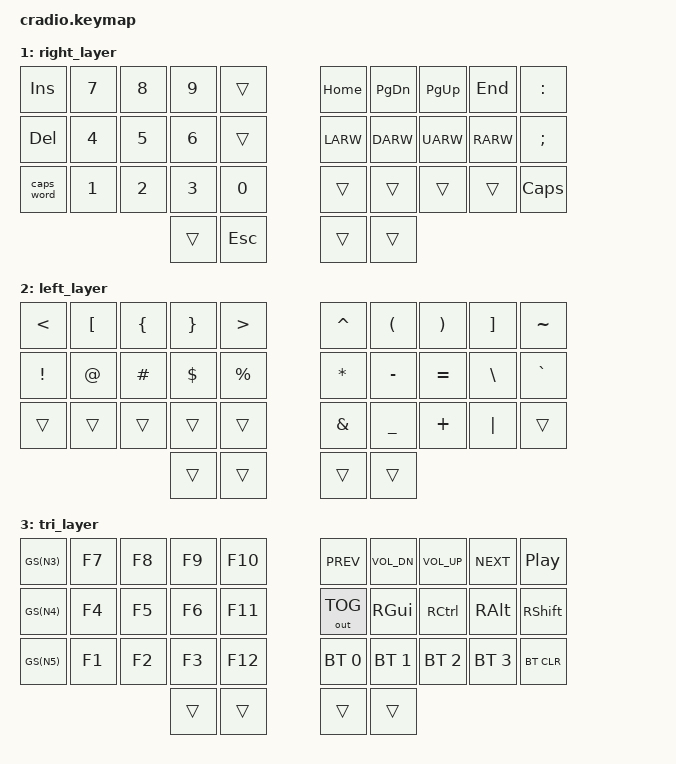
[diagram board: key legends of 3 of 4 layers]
// Copyright (c) 2022 The ZMK Contributors
// SPDX-License-Identifier: MIT

#include <behaviors.dtsi>
#include <dt-bindings/zmk/keys.h>
#include <dt-bindings/zmk/bt.h>
#include <dt-bindings/zmk/outputs.h>

/*           34 Keys
╭──────────────╮ ╭──────────────╮
│ 0  1  2  3  4│ │ 5  6  7  8  9│
│10 11 12 13 14│ │15 16 17 18 19│
│20 21 22 23 24│ │25 26 27 28 29│
╰────────╮30 31│ │32 33╭────────╯
         ╰─────╯ ╰─────╯         */

// Home row mods macro
#define HRML(k1,k2,k3,k4) &ht LSHFT k1  &ht LALT k2  &ht LCTRL k3  &ht LGUI k4
#define HRMR(k1,k2,k3,k4) &ht RGUI k1  &ht RCTRL k2  &ht RALT k3  &ht RSHFT k4

// GS - GUI+SHIFT, for screenshotting on mac
#define GS(k1) LS(LG(k1))

/ {
    combos {
        compatible = "zmk,combos";
        combo_lctrl {
            bindings = <&skq LCTRL>;
            key-positions = <1 2>;
            layers = <0 1 2>;
            require-prior-idle-ms = <100>;
        };
        combo_shift {
            bindings = <&skq LSHIFT>;
            key-positions = <7 8>;
            layers = <0 1 2>;
            require-prior-idle-ms = <100>;
        };
        combo_alt {
            bindings = <&skq LALT>;
            key-positions = <27 28>;
            layers = <0 1 2>;
            require-prior-idle-ms = <100>;
        };
        combo_cmd {
            bindings = <&skq LCMD>;
            key-positions = <21 22>;
            layers = <0 1 2>;
            require-prior-idle-ms = <100>;
        };
    };

    behaviors {
        skq: sticky_key_quick_release {
            compatible = "zmk,behavior-sticky-key";
            label = "STICKY_KEY_QUICK_RELEASE";
            #binding-cells = <1>;
            bindings = <&kp>;
            release-after-ms = <1000>;
            quick-release;
            ignore-modifiers;
        };
        ht: hold_tap {
            compatible = "zmk,behavior-hold-tap";
            #binding-cells = <2>;
            flavor = "tap-preferred";
            tapping-term-ms = <220>;
            quick-tap-ms = <150>;
            require-prior-idle-ms = <80>;
            bindings = <&kp>, <&kp>;
        };
    };

    conditional_layers {
        compatible = "zmk,conditional-layers";
        tri_layer {
            if-layers = <1 2>;
            then-layer = <3>;
        };
    };

    keymap {
        compatible = "zmk,keymap";
        default_layer {
            bindings = <
        //╭──────────┬──────────┬──────────┬──────────┬──────────╮   ╭──────────┬──────────┬──────────┬──────────┬──────────╮
        //│  Q       │  W       │  E       │  R       │  T       │   │  Y       │  U       │  I       │  O       │  P       │
            &kp Q      &kp W      &kp E      &kp R      &kp T          &kp Y      &kp U      &kp I      &kp O      &kp P
        //├──────────┼──────────┼──────────┼──────────┼──────────┤   ├──────────┼──────────┼──────────┼──────────┼──────────┤
        //│  A       │  S       │  D       │  F       │  G       │   │  H       │  J       │  K       │  L       │ ' "      │
            HRML(A,        S,         D,         F)     &kp G          &kp H      HRMR(J,        K,         L,        SQT)
        //├──────────┼──────────┼──────────┼──────────┼──────────┤   ├──────────┼──────────┼──────────┼──────────┼──────────┤
        //│  Z       │  X       │  C       │  V       │  B       │   │  N       │  M       │ , <      │ . >      │ / ?      │
            &kp Z      &kp X      &kp C      &kp V      &kp B          &kp N      &kp M      &kp COMMA  &kp DOT    &kp FSLH
        //╰──────────┴──────────┴──────────┼──────────┼──────────┤   ├──────────┼──────────┼──────────┴──────────┴──────────╯
                                            &lt 2 TAB   &kp ENTER     &kp SPACE  &lt 1 BSPC
        //                                 ╰──────────┴──────────╯   ╰──────────┴──────────╯
            >;
        };

        right_layer {
            bindings = <
        //╭──────────┬──────────┬──────────┬──────────┬──────────╮   ╭──────────┬──────────┬──────────┬──────────┬──────────╮
        //│ INSERT   │  7       │  8       │  9       │          │   │ HOME     │ PAGE DN  │ PAGE UP  │ END      │  :       │
            &kp INS    &kp N7     &kp N8     &kp N9     &trans         &kp HOME   &kp PG_DN  &kp PG_UP  &kp END    &kp COLON
        //├──────────┼──────────┼──────────┼──────────┼──────────┤   ├──────────┼──────────┼──────────┼──────────┼──────────┤
        //│ DELETE   │  4       │  5       │  6       │          │   │ LEFT     │ DOWN     │ UP       │ RIGHT    │  ;       │
            &kp DEL    &kp N4     &kp N5     &kp N6     &trans         &kp LARW   &kp DARW   &kp UARW   &kp RARW   &kp SEMI
        //├──────────┼──────────┼──────────┼──────────┼──────────┤   ├──────────┼──────────┼──────────┼──────────┼──────────┤
        //│ CAPS     │  1       │  2       │  3       │  0       │   │          │          │          │          │  CAPS L  │
           &caps_word  &kp N1     &kp N2     &kp N3     &kp N0         &trans     &trans     &trans     &trans     &kp CAPS
        //╰──────────┴──────────┴──────────┼──────────┼──────────┤   ├──────────┼──────────┼──────────┴──────────┴──────────╯
                                             &trans     &kp ESC        &trans     &trans
        //                                 ╰──────────┴──────────╯   ╰──────────┴──────────╯
            >;
        };

        left_layer {
            bindings = <
        //╭──────────┬──────────┬──────────┬──────────┬──────────╮   ╭──────────┬──────────┬──────────┬──────────┬──────────╮
        //│ <        │  [       │  {       │  }       │ >        │   │  ^       │  (       │  )       │  ]       │  ~       │
            &kp LT     &kp LBKT   &kp LBRC   &kp RBRC   &kp GT         &kp CARET  &kp LPAR   &kp RPAR   &kp RBKT   &kp TILDE
        //├──────────┼──────────┼──────────┼──────────┼──────────┤   ├──────────┼──────────┼──────────┼──────────┼──────────┤
        //│  !       │  @       │  #       │  $       │  %       │   │  *       │  -       │  =       │  \       │  `       │
            &kp EXCL   &kp AT     &kp HASH   &kp DLLR   &kp PRCNT      &kp ASTRK  &kp MINUS  &kp EQUAL  &kp BSLH   &kp GRAVE
        //├──────────┼──────────┼──────────┼──────────┼──────────┤   ├──────────┼──────────┼──────────┼──────────┼──────────┤
        //│          │          │          │          │          │   │  &       │  _       │  +       │  │       │          │
            &trans     &trans     &trans     &trans     &trans         &kp AMPS   &kp UNDER  &kp PLUS   &kp PIPE   &trans
        //╰──────────┴──────────┴──────────┼──────────┼──────────┤   ├──────────┼──────────┼──────────┴──────────┴──────────╯
                                             &trans     &trans         &trans     &trans
        //                                 ╰──────────┴──────────╯   ╰──────────┴──────────╯
            >;
        };

        tri_layer {
            bindings = <
        //╭──────────┬──────────┬──────────┬──────────┬──────────╮   ╭──────────┬──────────┬──────────┬──────────┬──────────╮
        //│ ss scr   │   F7     │   F8     │   F9     │  F10     │   │          │          │          │          │          │
            &kp GS(N3)  &kp F7     &kp F8     &kp F9    &kp F10       &kp C_PREV &kp C_VOL_DN &kp C_VOL_UP &kp C_NEXT &kp C_PP
        //├──────────┼──────────┼──────────┼──────────┼──────────┤   ├──────────┼──────────┼──────────┼──────────┼──────────┤
        //│ ss sel   │   F4     │   F5     │   F6     │  F11     │   │          │          │          │          │          │
            &kp GS(N4)  &kp F4     &kp F5     &kp F6    &kp F11     &out OUT_TOG &kp RGUI   &kp RCTRL  &kp RALT   &kp RSHFT 
        //├──────────┼──────────┼──────────┼──────────┼──────────┤   ├──────────┼──────────┼──────────┼──────────┼──────────┤
        //│ ss opt   │  F1      │  F2      │ F3       │ F12      │   │          │          │          │          │          │
            &kp GS(N5) &kp F1     &kp F2    &kp F3     &kp F12 &bt BT_SEL 0 &bt BT_SEL 1 &bt BT_SEL 2 &bt BT_SEL 3 &bt BT_CLR
        //╰──────────┴──────────┴──────────┼──────────┼──────────┤   ├──────────┼──────────┼──────────┴──────────┴──────────╯
                                             &trans     &trans         &trans     &trans
        //                                 ╰──────────┴──────────╯   ╰──────────┴──────────╯
            >;
        };
    };
};
